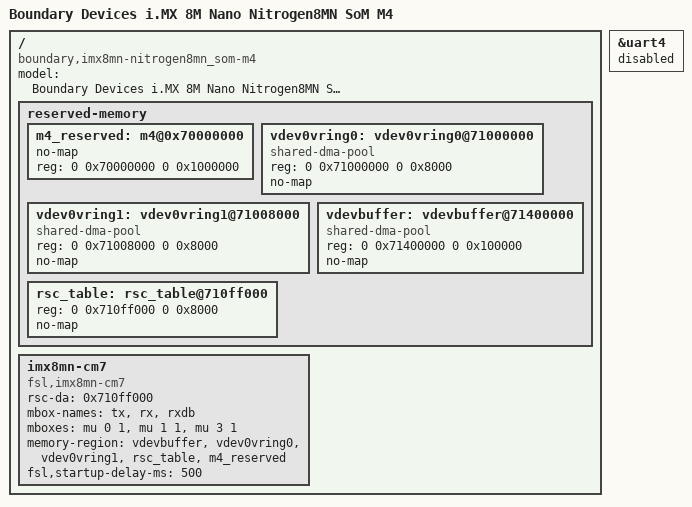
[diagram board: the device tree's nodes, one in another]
// SPDX-License-Identifier: (GPL-2.0+ OR MIT)
/*
 * Copyright 2020 Boundary Devices
 */

#include "imx8mn-nitrogen8mn_som.dts"

/ {
	model = "Boundary Devices i.MX 8M Nano Nitrogen8MN SoM M4";
	compatible = "boundary,imx8mn-nitrogen8mn_som-m4", "fsl,imx8mn";

	reserved-memory {
		#address-cells = <2>;
		#size-cells = <2>;
		ranges;

		m4_reserved: m4@0x70000000 {
			no-map;
			reg = <0 0x70000000 0 0x1000000>;
		};

		vdev0vring0: vdev0vring0@71000000 {
			compatible = "shared-dma-pool";
			reg = <0 0x71000000 0 0x8000>;
			no-map;
		};

		vdev0vring1: vdev0vring1@71008000 {
			compatible = "shared-dma-pool";
			reg = <0 0x71008000 0 0x8000>;
			no-map;
		};

		vdevbuffer: vdevbuffer@71400000 {
			compatible = "shared-dma-pool";
			reg = <0 0x71400000 0 0x100000>;
			no-map;
		};

		rsc_table: rsc_table@710ff000 {
			reg = <0 0x710ff000 0 0x8000>;
			no-map;
		};
	};

	imx8mn-cm7 {
		compatible = "fsl,imx8mn-cm7";
		rsc-da = <0x710ff000>;
		mbox-names = "tx", "rx", "rxdb";
		mboxes = <&mu 0 1
			  &mu 1 1
			  &mu 3 1>;
		memory-region = <&vdevbuffer>, <&vdev0vring0>, <&vdev0vring1>,
				<&rsc_table>, <&m4_reserved>;
		status = "okay";
		fsl,startup-delay-ms = <500>;
	};
};

&uart4 {
	status = "disabled";
};
